# CY8C5268AXI_LP047 register map
File version: 0.1
CY8C52LP
Registers are 8-bit, read-write, no defined reset value unless marked. A register's access mark holds for its fields unless they carry their own. Offsets are from the block's base; lines under a group give offsets from that group; [hi:lo] are bit positions; {n}, {i} and the like mark numbered series; 'fields as' and 'values as' point back to an identical list; <NAME> marks a mode.

## Memory map
0x40006424 HSYNC size 0x151
0x40006425 HORIZ size 0x71
0x40006426 VSYNC size 0x71
0x40006447 UART size 0x121
0x40006476 PIXEL size 0x1
0x40006477 VERT size 0x121

## PIXEL
Base 0x40006476
0x00 PIXEL_CONTROL_REG

## HSYNC
Base 0x40006424
0x00 HSYNC_COMPARE_Reg_ — UDB.D0 - Assigned Compare Value
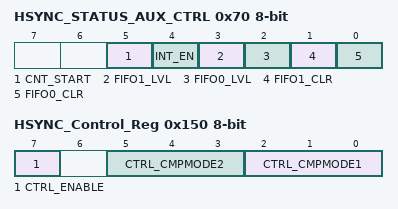
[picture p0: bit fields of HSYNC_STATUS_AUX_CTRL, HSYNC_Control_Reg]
0x70 HSYNC_STATUS_AUX_CTRL — UDB Auxilliary Control Register
  [5] CNT_START — FIFO0 clear
    0=E_CNT_START0 (Disable counter); 1=E_CNT_START1 (Enable counter)
  [4] INT_EN
    0=E_INT_EN0 (Interrupt disabled); 1=E_INT_EN1 (Interrupt enabled)
  [3] FIFO1_LVL — FIFO level
    0=E_FIFO_LVL_0 (FIFO LVL: input mode: FIFO not full; output mode: FIFO not empty); 1=E_FIFO_LVL_1 (FIFO LVL: input mode: FIFO at least 1/2 empty; output mode: FIFO at least 1/2 full)
  [2] FIFO0_LVL — FIFO level
    values as FIFO1_LVL
  [1] FIFO1_CLR — FIFO1 clear
    0=E_FIFO_CLR_0 (Normal FIFO operation); 1=E_FIFO_CLR_1 (Clear FIFO state)
  [0] FIFO0_CLR — FIFO0 clear
    values as FIFO1_CLR
0x150 HSYNC_Control_Reg — UDB Control Register - Assigned Control Register Value
  [7] CTRL_ENABLE — Enable the PWM
  [5:3] CTRL_CMPMODE2 — Compare mode 2
  [2:0] CTRL_CMPMODE1 — Compare mode 1

## UART
Base 0x40006447
0x00 TX_UART_TX_DATA — TX Data Register
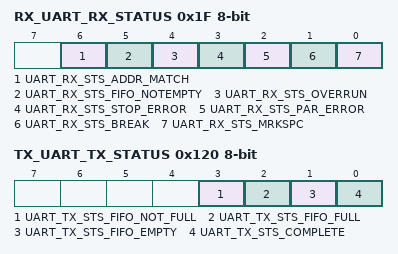
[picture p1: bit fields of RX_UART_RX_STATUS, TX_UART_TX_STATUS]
0x1F RX_UART_RX_STATUS — RX status register
  [6] UART_RX_STS_ADDR_MATCH ro, [5] UART_RX_STS_FIFO_NOTEMPTY ro, [4] UART_RX_STS_OVERRUN ro, [3] UART_RX_STS_STOP_ERROR ro, [2] UART_RX_STS_PAR_ERROR ro, [1] UART_RX_STS_BREAK ro, [0] UART_RX_STS_MRKSPC ro
0xDE RX_UART_RX_ADDRESS1 — RX Address1 Register
0xEE RX_UART_RX_ADDRESS2 — RX Address2 Register
0xFE RX_UART_RX_DATA — RX Data Register
0x120 TX_UART_TX_STATUS — TX status register
  [3] UART_TX_STS_FIFO_NOT_FULL ro, [2] UART_TX_STS_FIFO_FULL ro, [1] UART_TX_STS_FIFO_EMPTY ro, [0] UART_TX_STS_COMPLETE ro

## HORIZ
Base 0x40006425
Registers as HSYNC (with HSYNC read as HORIZ), without HSYNC_COMPARE_Reg_, HSYNC_Control_Reg; these are added or differ:
0x00 HORIZ__COMPARE1 — UDB.D0 - Assigned Compare1 Value
0x10 HORIZ__COMPARE2 — UDB.D1 - Assigned Compare2 Value
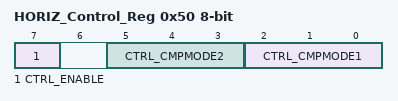
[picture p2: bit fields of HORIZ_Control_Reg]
0x50 HORIZ_Control_Reg — UDB Control Register - Assigned Control Register Value
  [7] CTRL_ENABLE — Enable the PWM
  [5:3] CTRL_CMPMODE2 — Compare mode 2
  [2:0] CTRL_CMPMODE1 — Compare mode 1

## VERT
Base 0x40006477
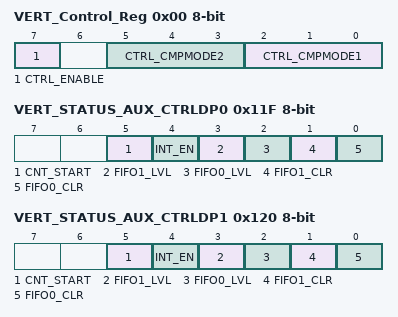
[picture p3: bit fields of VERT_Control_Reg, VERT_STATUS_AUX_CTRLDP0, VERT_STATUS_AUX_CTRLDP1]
0x00 VERT_Control_Reg — UDB Control Register - Assigned Control Register Value
  [7] CTRL_ENABLE — Enable the PWM
  [5:3] CTRL_CMPMODE2 — Compare mode 2
  [2:0] CTRL_CMPMODE1 — Compare mode 1
0xAF VERT_COMPARE_Reg 16-bit — UDB.D0 - Assigned Compare Value
0x11F VERT_STATUS_AUX_CTRLDP0 — UDB Auxilliary Control Register
  fields as HSYNC.HSYNC_STATUS_AUX_CTRL
0x120 VERT_STATUS_AUX_CTRLDP1 — UDB Auxilliary Control Register
  fields as HSYNC.HSYNC_STATUS_AUX_CTRL

## VSYNC
Base 0x40006426
Registers as HSYNC (with HSYNC read as VSYNC), without HSYNC_Control_Reg; these are added or differ:
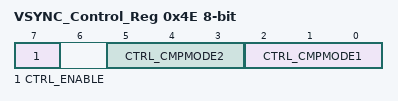
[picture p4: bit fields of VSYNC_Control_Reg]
0x4E VSYNC_Control_Reg — UDB Control Register - Assigned Control Register Value
  [7] CTRL_ENABLE — Enable the PWM
  [5:3] CTRL_CMPMODE2 — Compare mode 2
  [2:0] CTRL_CMPMODE1 — Compare mode 1
